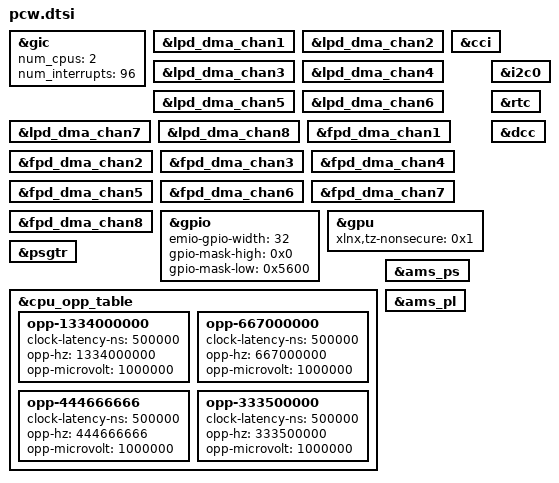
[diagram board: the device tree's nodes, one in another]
/*
 * CAUTION: This file is automatically generated by Xilinx.
 * Version: XSCT 
 * Today is: Fri Aug 29 13:00:17 2025
 */


&gic {
	num_cpus = <2>;
	num_interrupts = <96>;
};
&lpd_dma_chan1 {
	status = "okay";
};
&lpd_dma_chan2 {
	status = "okay";
};
&lpd_dma_chan3 {
	status = "okay";
};
&lpd_dma_chan4 {
	status = "okay";
};
&lpd_dma_chan5 {
	status = "okay";
};
&lpd_dma_chan6 {
	status = "okay";
};
&lpd_dma_chan7 {
	status = "okay";
};
&lpd_dma_chan8 {
	status = "okay";
};
&cci {
	status = "okay";
};
&fpd_dma_chan1 {
	status = "okay";
};
&fpd_dma_chan2 {
	status = "okay";
};
&fpd_dma_chan3 {
	status = "okay";
};
&fpd_dma_chan4 {
	status = "okay";
};
&fpd_dma_chan5 {
	status = "okay";
};
&fpd_dma_chan6 {
	status = "okay";
};
&fpd_dma_chan7 {
	status = "okay";
};
&fpd_dma_chan8 {
	status = "okay";
};
&gpio {
	emio-gpio-width = <32>;
	gpio-mask-high = <0x0>;
	gpio-mask-low = <0x5600>;
	status = "okay";
};
&gpu {
	status = "okay";
	xlnx,tz-nonsecure = <0x1>;
};
&i2c0 {
	status = "okay";
};
&rtc {
	status = "okay";
};
&psgtr {
	status = "okay";
};
&cpu_opp_table {
	/delete-node/ opp00 ;
	/delete-node/ opp01 ;
	/delete-node/ opp02 ;
	/delete-node/ opp03 ;
	opp-1334000000 {
		clock-latency-ns = <500000>;
		opp-hz = /bits/ 64 <1334000000>;
		opp-microvolt = <1000000>;
	};
	opp-667000000 {
		clock-latency-ns = <500000>;
		opp-hz = /bits/ 64 <667000000>;
		opp-microvolt = <1000000>;
	};
	opp-444666666 {
		clock-latency-ns = <500000>;
		opp-hz = /bits/ 64 <444666666>;
		opp-microvolt = <1000000>;
	};
	opp-333500000 {
		clock-latency-ns = <500000>;
		opp-hz = /bits/ 64 <333500000>;
		opp-microvolt = <1000000>;
	};
};
&ams_ps {
	status = "okay";
};
&ams_pl {
	status = "okay";
};
&dcc {
	status = "okay";
};
